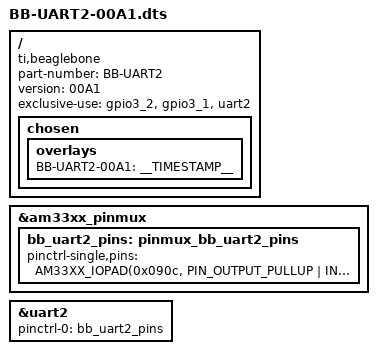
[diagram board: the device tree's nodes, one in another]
/*
 * Copyright (C) 2020 seeedstudio
 *
 * Virtual cape for UART2 on connector pins P9.21 P9.22
 *
 * This program is free software; you can redistribute it and/or modify
 * it under the terms of the GNU General Public License version 2 as
 * published by the Free Software Foundation.
 */

/dts-v1/;
/plugin/;

#include <dt-bindings/board/am335x-bbw-bbb-base.h>
#include <dt-bindings/pinctrl/am33xx.h>

/ {
	compatible = "ti,beaglebone", "ti,beaglebone-black", "ti,beaglebone-green";

	// identification
	part-number = "BB-UART2";
	version = "00A1";

	// resources this cape uses
	exclusive-use =
		"gpio3_2",		// uart2_txd
		"gpio3_1",		// uart2_rxd

		"uart2";		// hardware ip used

	/*
	 * Helper to show loaded overlays under: /proc/device-tree/chosen/overlays/
	 */
	fragment@0 {
		target-path="/";
		__overlay__ {

			chosen {
				overlays {
					BB-UART2-00A1 = __TIMESTAMP__;
				};
			};
		};
	};


	fragment@1 {
		target = <&am33xx_pinmux>;
		__overlay__ {
			bb_uart2_pins: pinmux_bb_uart2_pins {
				pinctrl-single,pins = <
					AM33XX_IOPAD(0x090c, PIN_OUTPUT_PULLUP | INPUT_EN | MUX_MODE6)
					AM33XX_IOPAD(0x0910, PIN_OUTPUT_PULLUP | INPUT_EN | MUX_MODE6)		
				>;
			};
		};
	};

	fragment@2 {
		target = <&uart2>;
		__overlay__ {
			status = "okay";
			pinctrl-names = "default";
			pinctrl-0 = <&bb_uart2_pins>;
		};
	};
};
